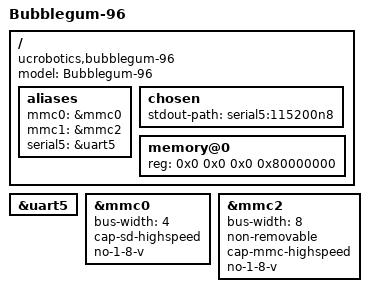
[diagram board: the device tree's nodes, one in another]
// SPDX-License-Identifier: GPL-2.0+
//
// Device Tree Source for Bubblegum-96
//
// Copyright (C) 2015 Actions Semi Co., Ltd.
// Copyright (C) 2018 Manivannan Sadhasivam <manivannan.sadhasivam@linaro.org>

/dts-v1/;
#include "s900.dtsi"

/ {
	model = "Bubblegum-96";
	compatible = "ucrobotics,bubblegum-96", "actions,s900";

	/*
	 * mmc1 is the eMMC (SD2) so "mmc 1:2" matches the vendor U-Boot
	 * and existing boot.scr files.
	 */
	aliases {
		mmc0 = &mmc0;
		mmc1 = &mmc2;
		serial5 = &uart5;
	};

	chosen {
		stdout-path = "serial5:115200n8";
	};

	memory@0 {
		device_type = "memory";
		reg = <0x0 0x0 0x0 0x80000000>;
	};
};

&uart5 {
	status = "okay";
};

/* uSD; no pinctrl driver, relies on the pinmux left by the boot ROM/SECM */
&mmc0 {
	status = "okay";
	bus-width = <4>;
	cap-sd-highspeed;
	no-1-8-v;
};

/* eMMC */
&mmc2 {
	status = "okay";
	bus-width = <8>;
	non-removable;
	cap-mmc-highspeed;
	no-1-8-v;
};
